# RL6842_IP_SVD register map
Vendor: Realtek
Registers are 32-bit, read-write, reset 0x0 unless marked. A register's access mark holds for its fields unless they carry their own. Offsets are from the block's base; [hi:lo] are bit positions; {n}, {i} and the like mark numbered series.

## captouch
Base 0x4101E000
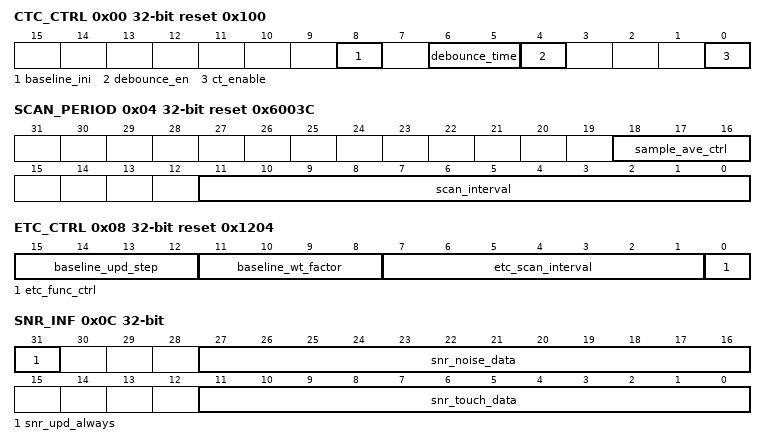
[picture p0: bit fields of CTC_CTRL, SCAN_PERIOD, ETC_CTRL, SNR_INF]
0x00 CTC_CTRL reset 0x100 — Captouch Control Register
  [8] baseline_ini — 1: Baseline initial function enable, HW will clear this bit to "0" after baseline initial
  [6:5] debounce_time — 2'b00: 2 times 2'b01: 3 times 2'b10: 4 times 2'b11: 5 times
  [4] debounce_en — 0: Disable 1: Enable
  [0] ct_enable — 0: CTC disable 1: CTC enable
0x04 SCAN_PERIOD reset 0x6003C — Scan Parameters Register
  [18:16] sample_ave_ctrl — ADC sampled number for average function average number=2^(sample_ave_ctrl+2)
  [11:0] scan_interval — Code: 0~4095 (0~0xFFF), unit is 1.024KHz cycle (1/32 32.768KHz). When this register is set to 0 or 1, HW will scan continuously and have no sleep time. Recommend value: 60~480ms
0x08 ETC_CTRL reset 0x1204 — Environment Tracking Control Register
  [15:12] baseline_upd_step — Baseline update step for all channel
  [11:8] baseline_wt_factor — Baseline update weight factor (ETC_factor_th) for all channel ETC_factor_th=2^baseline_wt_factor
  [7:1] etc_scan_interval — ETC update interval between scan period (sleep time) for all channel Interval=(etc_scan_interval+1)*scan_period
  [0] etc_func_ctrl — Environmental cap tracking calibration function 0: Disable 1: Enable
0x0C SNR_INF — Signal Noise Ratio Register
  [31] snr_upd_always — 1: Update SNR info no matter touch or not (used only in debug function)
  [27:16] snr_noise_data — Noise peak to peak signal raw data for SNR monitor
  [11:0] snr_touch_data — Raw data of touch(signal-baseline)for SNR monitor
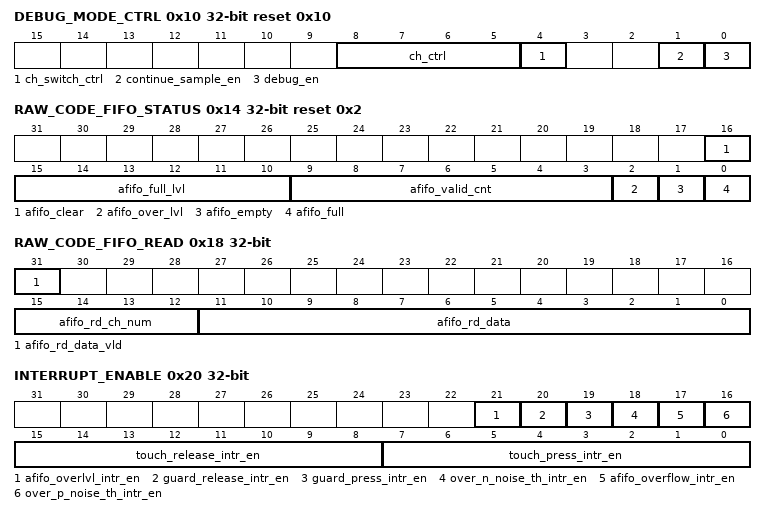
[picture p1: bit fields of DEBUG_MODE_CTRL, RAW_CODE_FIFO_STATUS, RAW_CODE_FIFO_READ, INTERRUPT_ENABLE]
0x10 DEBUG_MODE_CTRL reset 0x10 — Debug and Channel Swith Mode Register
  [8:5] ch_ctrl — Scan channel control 0000: channel 0 0001: channel 1 0010: channel 2 0011: channel 3 0100: channel 4 0101: channel 5 0110: channel 6 0111: channel 7 1000: channel 8 (guard sensor)
  [4] ch_switch_ctrl — Scan channel switch control 0: Auto switch function disable (manual switch by ch_ctrl) 1: Auto switch to next channel (channel 0 --> channel 3 --> channel 0)
  [1] continue_sample_en — continue sample one channel mode enable, only take effect in debug mode 1: enable 0: disable
  [0] debug_en — Debug mode enable 0: Disable 1: Enable
0x14 RAW_CODE_FIFO_STATUS access per field reset 0x2 — FIFO Status Register
  [16] afifo_clear wo — clear the FIFO data
  [15:10] afifo_full_lvl rw — user define the full level for afifo, the valid value is from 0 to 63
  [9:3] afifo_valid_cnt ro — Raw code FIFO valid cnt(push unit number which can be read)
  [2] afifo_over_lvl ro — 0: Raw code FIFO not over level 1: Raw code FIFO over level
  [1] afifo_empty ro — 0: Raw code FIFO not empty 1: Raw code FIFO empty
  [0] afifo_full ro — 0: Raw code FIFO not oveflow (not full) 1: Raw code FIFO overflow(full)
0x18 RAW_CODE_FIFO_READ ro — FIFO Read Register
  [31] afifo_rd_data_vld — Read data from raw code FIFO valid
  [15:12] afifo_rd_ch_num — Read data from raw code FIFO channel number
  [11:0] afifo_rd_data — Read data from raw code FIFO data
0x20 INTERRUPT_ENABLE
  [21] afifo_overlvl_intr_en — Raw code FIFO over level enable
  [20] guard_release_intr_en — Guard sensor release enable
  [19] guard_press_intr_en — Guard sensor press enable
  [18] over_n_noise_th_intr_en — Negative noise threshold overflow enable
  [17] afifo_overflow_intr_en — Raw code FIFO overflow enable
  [16] over_p_noise_th_intr_en — Positive noise threshold overflow enable
  [15:8] touch_release_intr_en — Channelx single touch release enable, x is 0~7
  [7:0] touch_press_intr_en — Channelx single touch press enable, x is 0~7
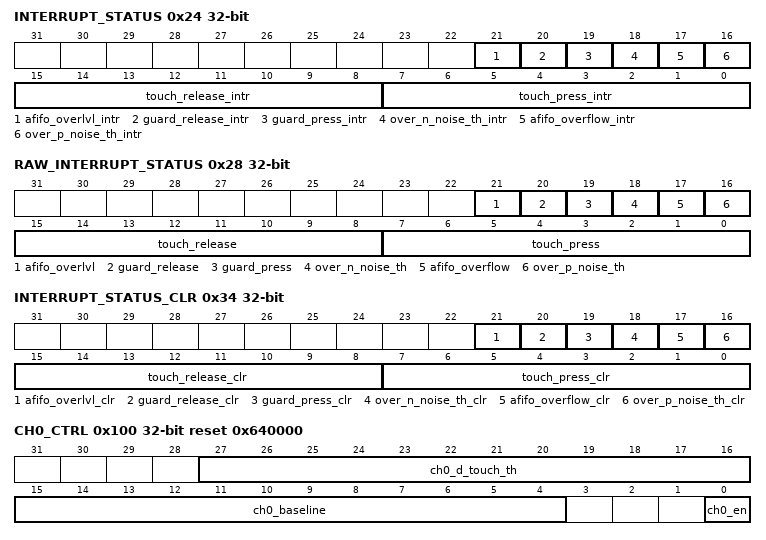
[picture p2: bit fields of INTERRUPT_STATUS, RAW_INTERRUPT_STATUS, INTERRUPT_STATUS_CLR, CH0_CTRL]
0x24 INTERRUPT_STATUS ro
  [21] afifo_overlvl_intr — Raw code FIFO over level interrupt
  [20] guard_release_intr — Guard sensor release interrupt
  [19] guard_press_intr — Guard sensor press interrupt
  [18] over_n_noise_th_intr — Negative noise threshold overflow interrupt
  [17] afifo_overflow_intr — Raw code FIFO overflow interrupt
  [16] over_p_noise_th_intr — Positive noise threshold overflow interrupt
  [15:8] touch_release_intr — Channelx single touch release interrupt, x is 0~7
  [7:0] touch_press_intr — Channelx single touch press interrupt, x is 0~7
0x28 RAW_INTERRUPT_STATUS ro
  [21] afifo_overlvl — Raw code FIFO over level raw interrupt
  [20] guard_release — Guard sensor release raw interrupt
  [19] guard_press — Guard sensor press raw interrupt
  [18] over_n_noise_th — Negative noise threshold overflow raw interrupt
  [17] afifo_overflow — Raw code FIFO overflow raw interrupt
  [16] over_p_noise_th — Positive noise threshold overflow raw interrupt
  [15:8] touch_release — Channelx single touch release raw interrupt, x is 0~7
  [7:0] touch_press — Channelx single touch press raw interrupt, x is 0~7
0x30 INTERRUPT_ALL_CLR — Interrupt All Clear Register
  [0] intr_all_clr — Write "1" to this register to clear the combined interrupts, all individual interrupts, interrupt status register and raw interrupt status register.
0x34 INTERRUPT_STATUS_CLR — Interrupt Clear Register
  [21] afifo_overlvl_clr — Clear raw code FIFO over level raw interrupt and related register
  [20] guard_release_clr — Clear guard sensor release interrupt and related register
  [19] guard_press_clr — Clear guard sensor press interrupt and related register
  [18] over_n_noise_th_clr — Clear negative noise threshold overflow interrupt and related register
  [17] afifo_overflow_clr — Clear raw code FIFO overflow interrupt and related register
  [16] over_p_noise_th_clr — Clear positive noise threshold overflow interrupt and related register
  [15:8] touch_release_clr — Clear channelx single touch release interrupt and related register
  [7:0] touch_press_clr — Clear channelx single touch press interrupt and related register
0x40 DEBUG_SEL — Debug Select Register
  [2:0] dbg_sel — Debug information selection 0: dbg_clkrst 1: dbg_apbslv 2: dbg_ctrl 3: dbg_decision 4: dbg_adc_arb Others: dbg_clkrst
0x44 DEBUG_PORT ro — Debug Register
  [31:0] dbg_port — Debug port output value,depend on dbg_sel value
0x48 ECO_USE0
  [31:0] eco_use0 — For ECO use
0x4C ECO_USE1
  [31:0] eco_use1 — For ECO use
0x50 CTC_COMP_VERSION reset 0x20180123 — Version Register
  [31:0] comp_version — CTC version number
0x100 CH0_CTRL reset 0x640000 — Channel 0 Control Register
  [27:16] ch0_d_touch_th — Difference threshold data of touch judgement for channel 0. It needs to be configured during development, (0x0~0xFFF) (0~4095). Init number=0x1E Recommend data=80%*(signal-baseline)
  [15:4] ch0_baseline — Digital baseline data of channel 0. Init number=0x0 It can be initialed by HW when baseline initial function enabled, and can be updated automatically by HW when ETC function enabled. It could be configured by manual tuning.
  [0] ch0_en — Cap sensor activity control of channel 0 0: Disable 1: Enable
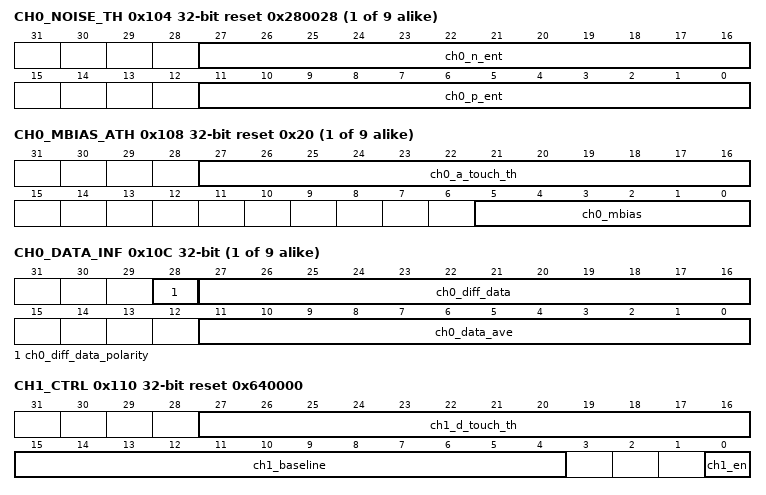
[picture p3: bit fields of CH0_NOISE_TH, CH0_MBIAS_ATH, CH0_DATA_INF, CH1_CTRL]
{0x104+0x10*i} CH{i}_NOISE_TH reset 0x280028 (i=0..8) — Channel {i} Noise Threshold Register
  [27:16] ch{i}_n_ent — The environmental negative noise threshold: the negative maximum capacitance change of raw data that is still considered an environment change.
  [11:0] ch{i}_p_ent — The environmental positive noise threshold: the positive maximum capacitance change of raw data that is still considered an environment change.
{0x108+0x10*i} CH{i}_MBIAS_ATH reset 0x20 (i=0..8) — Channel {i} Mbias
  [27:16] ch{i}_a_touch_th — Absolute threshold data of touch judgement for channel {i}. It can be updated by HW when baseline initial function or ETC function enabled, a_touch_th=baseline-d_touch_th, manual tuning when ETC disabled, (0x0~0xFFF). Recommended data=80%*signal
  [5:0] ch{i}_mbias — Touch mbias current [5:0] 8u/4u/2u/1u/0.5u/0.25u for channel {i}
{0x10C+0x10*i} CH{i}_DATA_INF (i=0..8) — Channel {i} Dtouch Register
  [28] ch{i}_diff_data_polarity — Polarity of ch{i}_diff_data 0: ch{i}_data_ave<baseline 1: ch{i}_data_ave>=baseline
  [27:16] ch{i}_diff_data — Difference digital data of channel{i} between ch{i}_data_ave and baseline
  [11:0] ch{i}_data_ave — Average of channel {i} raw code
0x110 CH1_CTRL reset 0x640000 — Channel 0 Control Register
  [27:16] ch1_d_touch_th — Difference threshold data of touch judgement for channel 1. It needs to be configured during development, (0x0~0xFFF) (0~4095). Init number=0x1E Recommend data=80%*(signal-baseline)
  [15:4] ch1_baseline — Digital baseline data of channel 1. Init number=0x0 It can be initialed by HW when baseline initial function enabled, and can be updated automatically by HW when ETC function enabled. It could be configured by manual tuning.
  [0] ch1_en — Cap sensor activity control of channel 1 0: Disable 1: Enable
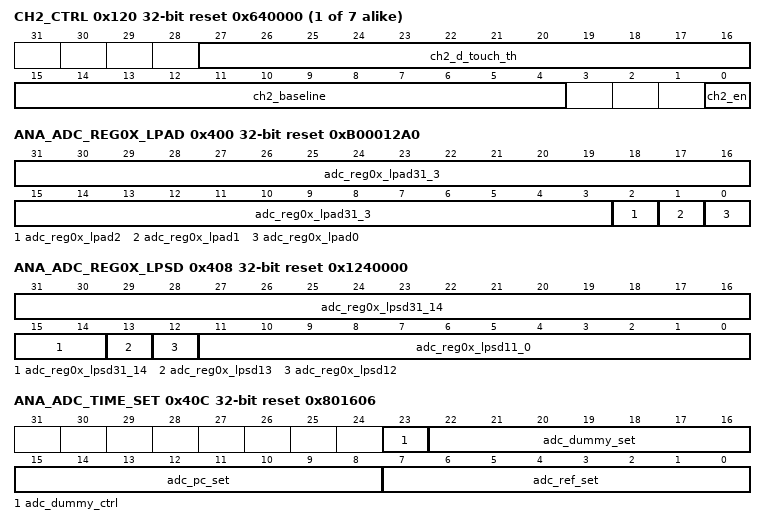
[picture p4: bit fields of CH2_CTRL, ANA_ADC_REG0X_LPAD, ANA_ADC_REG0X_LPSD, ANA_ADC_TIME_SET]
{0x100+0x10*i} CH{i}_CTRL reset 0x640000 (i=2..8) — Channel {i} Control Register
  [27:16] ch{i}_d_touch_th — Difference threshold data of touch judgement for channel {i}. It needs to be configured during development, (0x0~0xFFF) (0~4095). Init number=0x1E Recommend data=80%*(signal-baseline)
  [15:4] ch{i}_baseline — Digital baseline data of channel {i}. Init number=0x0 It can be initialed by HW when baseline initial function enabled, and can be updated automatically by HW when ETC function enabled. It could be configured by manual tuning.
  [0] ch{i}_en — Cap sensor activity control of channel {i} 0: Disable 1: Enable
0x400 ANA_ADC_REG0X_LPAD access per field reset 0xB00012A0 — Analog ADC REG0X_LPAD Register
  [31:3] adc_reg0x_lpad31_3 rw — Bit[31:3] of analog ADC port REG0X_LPAD. For every bit: [31:30]: VSET[1: 0] 11: 1.89V 10: 1.80V 01: 1.71V 00: 1.62V [29]: sel_ln 1: Comparator low noise for LSB 6 bits [28]: sel_lna 1: Comparator low noise for ALL bits [27:23]: dummy [22]: reg_enTG 1: Enable transmission gate [21:16]: bypassen[5:0], input bypass resistor 1: 1V mode 0: 3.3V mode [15]: reg_diode 1: Enable diode protect [14]: reg_meta 1: Enable meta detect [13: 12]: reg_mpdec<1: 0>, meta detect time 00: short [11]: reg_revckda 1: Rever ckdata [10:8]: reg_vref_sel[2: 0] 000: 0.70V 001: 0.75V 010: 0.80V 011: 0.85V 100: 0.90V 101: 0.95V 110: 1.00V 111: 1.05V [7:5]: reg_ldo_sel[2: 0] 000: 0.70V 001: 0.75V 010: 0.80V 011: 0.85V 100: 0.90V 101: 0.95V 110: 1.00V 111: 1.05V [4]: reg_delay, clk delay 0: short [3]: reg_ck 1: Clock from external
  [2] adc_reg0x_lpad2 ro — Bit[2] of analog ADC port REG0X_LPAD, pow_ref, pow ADC refgen
  [1] adc_reg0x_lpad1 ro — Bit[1] of analog ADC port REG0X_LPAD, pow, pow adc
  [0] adc_reg0x_lpad0 ro — Bit[0] of analog ADC port REG0X_LPAD, power LDO/mbias/res ladder, enable power cut/ldo
0x404 ANA_ADC_REG1X_LPAD — Analog ADC REG1X_LPAD Register
  [31:6] adc_reg1x_lpad31_6 — [31:8]: Reserved [7:6]: reg_vcmin[1: 0], vcmin voltage set 00: 0.45V 01: 0.44V 10: 0.43V 11: 0.42V
0x408 ANA_ADC_REG0X_LPSD access per field reset 0x1240000 — Analog ADC REG0X_LPSD Register
  [31:14] adc_reg0x_lpsd31_14 rw — dummy
  [13] adc_reg0x_lpsd13 ro — POW_I, power on BG current
  [12] adc_reg0x_lpsd12 ro — POW_BG, power on BG
  [11:0] adc_reg0x_lpsd11_0 rw — dummy
0x40C ANA_ADC_TIME_SET reset 0x801606 — Analog ADC Time Register
  [23] adc_dummy_ctrl — 1: REG0X_LPAD[2] is sync with REG0X_LPAD[0]. At this time, adc_reg0x_lpad2 can't take effect. 0: the delay of REG0X_LPAD[2] is controlled by adc_dummy_set. At this time, adc_reg0x_lpad2 can take effect.
  [22:16] adc_dummy_set — Time between REG0X_LPAD[0] and REG0X_LPAD[2] , unit is ctc clock cycle. This time is valid only when adc_dummy_ctrl is 0. time = (adc_dummy_set+1)*cycle
  [15:8] adc_pc_set — Time between REG0X_LPSD12 and REG0X_LPAD[0] power LDO/mbias/res ladder, unit is ctc clock cycle. time = (adc_pc_set+2)*cycle
  [7:0] adc_ref_set — Time between REG0X_LPAD[2] power_ref and REG0X_LPAD[1] pow_adc, unit is ctc clock cycle. time = (adc_ref_set+2)*cycle
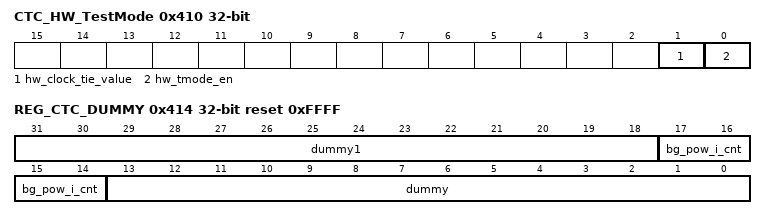
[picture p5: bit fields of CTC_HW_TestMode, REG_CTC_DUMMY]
0x410 CTC_HW_TestMode — Captouch_Hardware_Test_Mode Register
  [1] hw_clock_tie_value — this value is the clock tied value in captouch hardware test mode
  [0] hw_tmode_en — 0: hardware test mode disabled 1: hardware test mode enabled, the clock sent to AUX Analog from captouch is tie to fixed value, which is depent on hw_clock_tie_value( 410h[1] )
0x414 REG_CTC_DUMMY reset 0xFFFF — Captouch Dummy Register
  [31:18] dummy1 — dummy register
  [17:14] bg_pow_i_cnt — ECO: counter for BG_POW_I , unit is ctc clock cycle.
  [13:0] dummy
